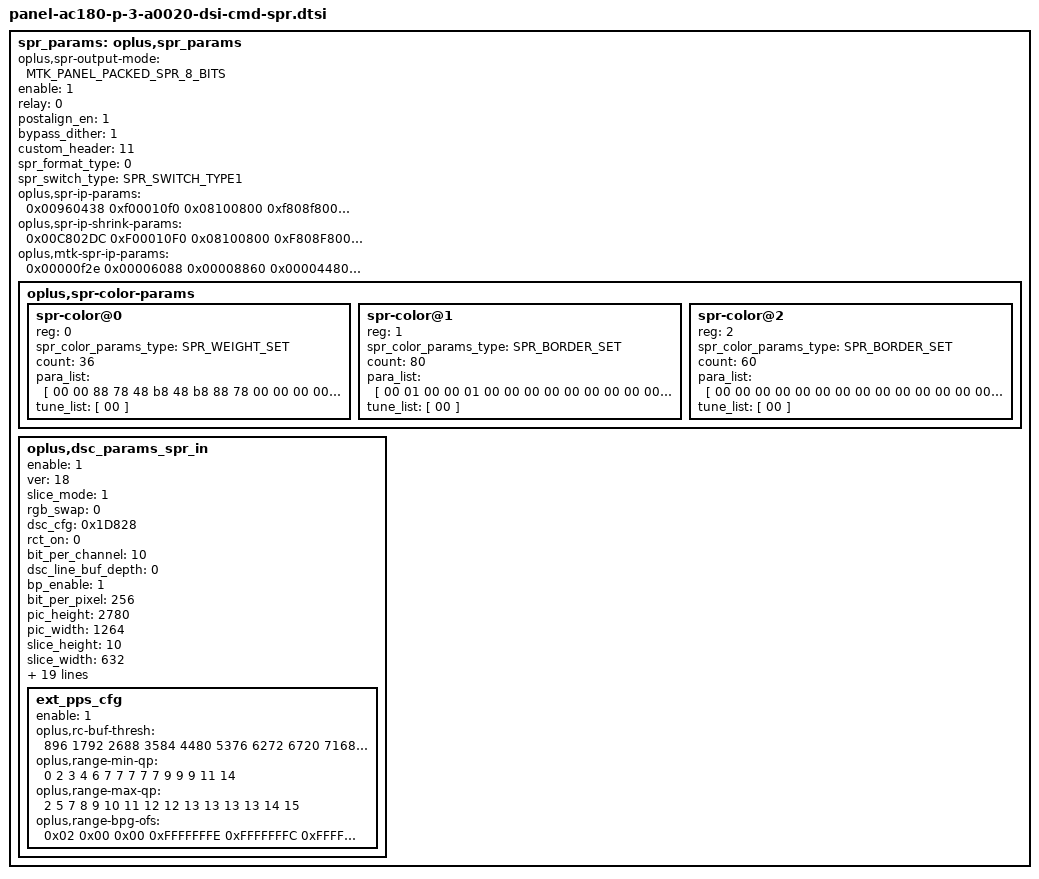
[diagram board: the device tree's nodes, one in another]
	spr_params: oplus,spr_params {
		oplus,spr-output-mode = <MTK_PANEL_PACKED_SPR_8_BITS>;
		enable = <1>;
		relay = <0>;
		postalign_en = <1>;
		bypass_dither = <1>;
		custom_header = <11>;
		spr_format_type = <0>;
		spr_switch_type = <SPR_SWITCH_TYPE1>;
		oplus,spr-ip-params = <
			0x00960438
			0xf00010f0
			0x08100800
			0xf808f800
			0x08000808
			0x00080010
			0x08000000
			0x10120000
			0x00121000
			0x10001012
			0x01f20012
			0x22010001
			0x02000220
			0x20040003
			0x00040003
			0x20040004
			0x20040003
			0x00040003
			0x00040004
			0x80808080
			0x80808040
			0x80408080
			0x00000000
			0x00000000
			0x00000000
			0x00000000
			0x00800000
			0x01080001
			0x08080800
			0x00808080
			0x80808080
			0x08008080
			0x80808080
			0x10533080
			0x50013551
			0x53355335
			0x35011335
			0x55531003
			0x53355335
			0x00000335
			0x00000000
			0x00000000
			0x00000000
			0x00000000
			0x00000000
			0x00000000
			0x00000000
			0x00000000
			0x00000000
			0x00000000
			0x00000000
			0x00000000
			0x00000000
			0x00000000
			0x00000000
			0x00000000
			0x00000000
			0x00000000
			0x00000000
			0x00000000
			0x00000000
			0x00000000
			0x00000000
			0x00000000
			0x00000000
			0x00000000
			0x00000000
			0x00000000
			0x00000000
			0x00000000
			0x00000000
			0x00000000
			0x0000007f
			0x00000000
			0x00000000
			0x00000000
			0x00000000
			0x00000000
			0x00000000
			0x00000000
			0x00000000
			0x00000000
			0x00000000
			0x00000000
			0x00000000
			0x00000000
			0x00000000
			0x00000000
			0x00000000
			0x00000000
			0x00000000
			0x00000000
			0x00000000
			0x00000000
			0x00000000
			0x00000000
			0x00000000
			0x00000000
			0x00000000
			0x00000000
			0x00000000
			0x00000000
			0x00000000
			0x00000000
			0x00000000
			0x00000000
			0x00000000
			0x00000000
			0x00000000
			0x00000000
			0x00000000
			0x00000000
			0x00000000
			0x00000000
			0x00000000
			0x00000000
			0x00000000
			0x00000000
			0x00000000
			0x00000000
			0x00000000
			0x00000000
			0x00000000
			0x00000000
			0x00000000
			0x00000000
			0x00000000
			0x00000000
			0x00000000
			0x00000000
			0x00000000
			0x00000000
			0x00000000
			0x00000000
			0x00000000
			0x00000000
			0x00000000
			0x00000000
			0x00000000
			0x00000000
			0x00000000
			0x00000000
			0x00000000
			0x00000000
			0x00000000
			0x00000000
			0x00000000
			0x00000000
			0x00000000
			0x00000000
			0x00000000
			0x00000000
			0x00000000
			0x00000000
			0x00000000
			0x00000000
			0x00000000
			0x00000000
			0x00000000
			0x00000000
			0x00000000
			0x00000000
			0x00000000
			0x00000000
			0x00000000
			0x00000000
			0x00000000
			0x00000000
			0x00000000
			0x00000000
			0x00000000
			0x00000000
			0x00000000
			0x00000000
			0x00000000
			0x00000000
			0x00000000
			0x00000000
			0x00000000
			0x00000000
			0x00000000
			0x00000000
			0x00000000
			0x00000000
			0x00000000
			0x00000000
			0x00000000
			0x00000000
			0x00000000
			0x00000000
			0x00000000
			0x00000000
			0x00000000
			0x00000000
			0x00000000
			0x00000000
			0x00000000
			0x00000000
			0x00000000
			0x00000000
			0x00000000
			0x00000000
			0x00000000
			0x00000000
			0x00000000
			0x00000000
			0x00000000
			0x00000000
			0x00000000
			0x00000000
			0x00000000
			0x00000000
			0x00000000
			0x00000000
			0x00000000
			0x00004000
			0x00000000
			0x00000000
			0x00000000
			0x00000000
			0x00000000
			0x00000000
			0x00000000
			0x00000000
			0x00000000
			0x00000000
			0x00000000
			0x00000000
			0x00000000
			0x00000000
			0x00000000
			0x00000000
			0x00000000
			0x00000000
			0x00000000
			0x00000000
			0x00000000
			0x00000000
			0x00000000
			0x00000000
			0x00000000
			0x00000000
			0x00000000
			0x00000000
			0x00000000
			0x00000000
			0x00000000
			0x00000000
			0x00000000
			0x00000000
			0x00000000
			0x00000000
			0x00000000
			0x00000000
			0x00000000
			0x00000000
			0x00000000
			0x00000000
			0x00000000
			0x00000000
			0x00000000
			0x00000000
			0x00000000
			0x00000000
			0x00000000
			0x00000000
			0x00000000
			0x00000000
			0x00000000
			0x00000000
			0x00000000
			0x00000000
			0x00000000
			0x00000000
			0x00000000
			0x00000000
			0x00000000
			0x00000000
			0x00000000
			0x00000000
			0x00000000
			0x00000000
			0x00000000
			0x00000000
			0x00000000
			0x00000000
			0x04000000
			0x00000000
			0x00000000
			0x00003000
			0x00000000
			0x00000000
			0x00000000
			0x00000000
			0x00000000
			0x00000000
			0x00000000
			0x00000000
			0x00000000
			0x00000000
			0x00000000
			0x00000000
			0x00000000
			0x00000000
			0x00000000
			0x00000000
			0x00000000
			0x00000000
			0x00000000
			0x00000000
			0x00000000
			0x00000000
			0x00000000
			0x00000000
			0x00000000
			0x00000000
			0x00000000
			0x00000000
			0x00000000
			0x00000000
			0x00000000
			0x00000000
			0x00000000
			0x00000000
			0x00000000
			0x00000000
			0x00000000
			0x00000000
			0x00000000
			0x00000000
			0x00000000
			0x00000000
			0x00000000
			0x00000000
			0x00000000
			0x00000000
			0x00000000
			0x00000000
			0x00000000
			0x00000000
			0x00000000
			0x00000000
			0x00000000
			0x00000000
			0x00000000
			0x00000000
			0x00000000
			0x00000000
			0x00000000
			0x00000000
			0x00000000
			0x00000000
			0x00000000
			0x00000000
			0x00000000
			0x00000000
			0x00000000
			0x00000000
			0x00000000
			0x00000000
			0x00000000
			0x00000000
			0x00000000
			0x00000000
			0x00000000
			0x00000000
			0x00000000
			0x00000000
			0x00000000
			0x00000000
			0x00000000
			0x00000000
			0x00000000
			0x00000000
			0x00000000
			0x00000000
			0x00000000
			0x00000000
			0x00000000
			0x00000000
			0x00000000
			0x00000000
			0x00000000
			0x00000000
			0x00000000
			0x00000000
			0x00000000
			0x00000000
			0x00000000
			0x00000000
			0x00000000
			0x00000000
			0x00000000
			0x00000000
			0x00000000
			0x00000000
			0x00000000
			0x00000000
			0x00000000
			0x00000000
			0x00000000
			0x00000000
			0x00000000
			0x00000000
			0x00000000
			0x00000000
			0x00000000
			0x00000000
			0x00000000
			0x00000000
			0x00000000
			0x00000000
			0x00000000
			0x00000000
			0x00000000
			0x00000000
			0x00000000
			0x00000000
			0x00000000
			0x00000000
			0x00000000
			0x00000000
			0x00000000
			0x00000000
			0x00000000
			0x00000000
			0x00000000
			0x00000000
			0x00000000
			0x00000000
			0x00000000
			0x00000000
			0x00000000
			0x00000000
			0x00000000
			0x00000000
			0x00000000
			0x00000000
			0x00000000
			0x00000000
			0x00000000
			0x00000000
			0x00000000
			0x00000000
			0x00000000
			0x00000000
			0x00000000
			0x00000000
			0x00000000
			0x00000000
			0x00000000
			0x00000000
			0x00000000
			0x00000000
			0x00000000
			0x00000000
			0x00000000
			0x00000000
			0x00000000
			0x00000000
			0x00000000
			0x00000000
			0x00000000
			0x00000000
			0x00000000
			0x00000000
			0x00000000
			0x00000000
			0x00000000
			0x00000000
			0x00000000
			0x00000000
			0x00000000
			0x00000000
			0x00000000
			0x00000000
			0x00000000
			0x00000000
			0x00000000
			0x00000000
			0x00000000
			0x00000000
			0x00000000
			0x00000000
			0x00000000
			0x00000000
			0x00000000
			0x00000000
			0x00000000
			0x00000000
			0x00000000
			0x00000000
			0x00000000
			0x00000000
			0x00000000
			0x00000000
			0x00000000
			0x00000000
			0x00000000
			0x00000000
			0x00000000
			0x00000000
			0x00000000
			0x00000000
			0x00000000
			0x00000000
			0x00000000
			0x00000000
			0x00000000
			0x00000000
			0x00000000
			0x00000000
			0x00000000
			0x00000000
			0x00000000
			0x00000000
			0x00000000
			0x00000000
			0x00000000
			0x00000000
			0x00000000
			0x00000000
			0x00000000
			0x00000000
			0x00000000
			0x00000000
			0x00000000
			0x00000000
			0x00000000
			0x00000000
			0x00000000
			0x00000000
			0x00000000
			0x00000000
			0x00000000
			0x00000000
			0x00000000
			0x00000000
			0x00000000
			0x00000000
			0x00000000
			0x00000000
			0x00000000
			0x00000000
			0x00000000
			0x00000000
			0x00000000
			0x00000000
			0x00000000
			0x00000000
			0x00000000
			0x00000000
			0x00000000
			0x00000000
			0x00000000
			0x00000000
			0x00000000
			0x00000000
			0x00000000
			0x00000000
			0x00000000
			0x00000000
			0x00000000
			0x00000000
			0x00000000
			0x00000000
			0x00000000
			0x00000000
			0x00000000
			0x00000000
			0x00000000
			0x00000000
			0x00000000
			0x00000000
			0x00000000
			0x00000000
			0x00000000
			0x00000000
			0x00000000
			0x00000000
			0x00000000
			0x00000000
			0x00000000
			0x00000000
			0x00000000
			0x00000000
			0x00000000
			0x00000000
			0x00000000
			0x00000000
			0x00000000
			0x00000000
			0x00000000
			0x00000000
			0x00000000
			0x00000000
			0x00000000
			0x00000000
			0x00000000
			0x00000000
			0x00000000
			0x00000000
			0x00000000
			0x00000000
			0x00000000
			0x00000000
			0x00000000
			0x00000000
			0x00000000
			0x00000000
			0x00000000
			0x00000000
			0x00000000
			0x00000000
			0x00000000
			0x00000000
			0x00000000
			0x00000000
			0x00000000
			0x00000000
			0x00000000
			0x00200000
			0x00000000
			0x00000000
			0x00000000
			0x00000000
			0x00000000
			0x00000000
			0x00000000
			0x00000001
			0x00001001
			0x00001001
			0x00001001
			0x00001001
			0x00000000
			0x00000000
			0x00000000
			0x00000000
			0x00000000
			0x00001000
			0x00001001
			0x00001001
			0x00001001
			0x00000001
			0x00000000
			0x00000000
			0x00000000
			0x00000000
			0x00000000
			0x00001001
			0x00001001
			0x00001001
			0x00001001
			0x00000001
			0x00000000
			0x00000000
			0x00000000
			0x00000000
			0x00000000
			0x00000000
			0x00000000
			0x00000000
			0x00000000
			0x00000000
			0x00000000
			0x00000000
			0x00000000
			0x00000000
			0x00000000
			0x00000000
			0x00000000
			0x00000000
			0x00000000
			0x00000000
			0x00000000
			0x00000000
			0x00000000
			0x00000000
			0x00000000
			0x00000000
			0x00000000
			0x00000000
			0x00000000
			0x00000000
			0x00000000
			0x00000000
			0x00000000
			0x00000000
			0x00000000
			0x00000000
			0x00000000
			0x00000000
			0x00000000
			0x00000000
			0x00000000
			0x00000000
			0x00000000
			0x00000000
			0x00000000
			0x00000000
			0x00000000
			0x00000000
			0x00000000
			0x00000000
			0x00000000
			0x00000000
			0x00000000
			0x00000000
			0x00000000
			0x00000000
			0x00000000
			0x00000000
			0x00000000
			0x00000000
			0x00000000
			0x00000000
			0x00000000
			0x00000000
			0x00000000
			0x00000000
			0x00000000
			0x00000000
			0x00000000
			0x00000000
			0x00000000
			0x00000000
			0x00000000
			0x00000000
			0x00000000
			0x00000000
			0x00000000
			0x00000000
			0x00000000
			0x00000000
			0x00000000
			0x00000000
			0x00000000
			0x00000000
			0x00000000
			0x00000000
			0x00000000
			0x00000000
			0x00000000
			0x00000000
			0x00000000
			0x00000000
			0x00000000
			0x00000000
			0x00000000
			0x00000000
			0x00000000
			0x00000000
			0x00000000
			0x00000000
			0x00000000
			0x00000000
			0x00000000
			0x00000000
			0x00000000
			0x00000000
			0x00000000
			0x00000000
			0x00000000
			0x00000000
			0x00000000
			0x00000000
			0x00000000
			0x00000000
			0x00000000
			0x00000000
			0x00000000
			0x00000000
			0x00000000
			0x00000000
			0x00000000
			0x00000000
			0x00000000
			0x00000000
			0x00000000
			0x00000000
			0x00000000
			0x00000000
			0x00000000
			0x00000000
			0x00000000
			0x00000000
			0x00000000
			0x00000000
			0x00000000
			0x00000000
			0x00000000
			0x00000000
			0x00000000
			0x00000000
			0x00000000
			0x00000000
			0x00000000
			0x00000000
			0x00000000
			0x00000000
			0x00000000
			0x00000000
			0x00000000
			0x00000000
			0x00000000
			0x00000000
			0x00000000
			0x00000000
			0x00000000
			0x00000000
			0x00000000
			0x00000000
			0x00000000
			0x00000000
			0x00000000
			0x00000000
			0x00000000
			0x00000000
			0x00000000
			0x00000000
			0x00000000
			0x00000000
			0x00000000
			0x00000000
			0x00000000
			0x00000000
			0x00000000
			0x00000000
			0x00000000
			0x00000000
			0x00000000
			0x00000706
		>;
		oplus,spr-ip-shrink-params = <
			0x00C802DC
			0xF00010F0
			0x08100800
			0xF808F800
			0x08000808
			0x00800010
			0x00800000
			0x10120000
			0x00121000
			0x10001012
			0x01F20012
			0x33010001
			0x02000330
			0x20040414
			0xF0040414
			0x241B0003
			0x20040414
			0xC0040414
			0x191AC003
			0x80805080
			0x80808080
			0x80508080
			0x00000000
			0x00000000
			0x00000000
			0x00000000
			0x00000000
			0x01010000
			0x08080800
			0x00808080
			0x80808080
			0x08008080
			0x80808080
			0x10533080
			0x50013551
			0x53355335
			0x35011335
			0x55531003
			0x53355335
			0x00000335
			0x00000003
			0x00000000
			0x00000000
			0x00000000
			0x00000000
			0x00000000
			0x0000007F
			0x00000000
			0x00000000
			0x00000000
			0x00000000
			0x00000000
			0x00000000
			0x00000000
			0x00000000
			0x00000000
			0x00000000
			0x00000000
			0x00000000
			0x00000000
			0x00000000
			0x00000000
			0x00000000
			0x00000000
			0x00000000
			0x00000000
			0x00000000
			0x00000000
			0x00000000
			0x00000000
			0x00000000
			0x00000000
			0x00000000
			0x00000000
			0x00000000
			0x00000000
			0x00000000
			0x00000000
			0x00000000
			0x00000000
			0x00000000
			0x00000000
			0x00000000
			0x00000000
			0x00000000
			0x00000000
			0x00000000
			0x00000000
			0x00000000
			0x00000000
			0x00000000
			0x00000000
			0x00000000
			0x00000000
			0x00000000
			0x00000000
			0x00000000
			0x00000000
			0x00000000
			0x00000000
			0x00000000
			0x00000000
			0x00000000
			0x00000000
			0x00000000
			0x00000000
			0x00000000
			0x00000000
			0x00000000
			0x00000000
			0x00000000
			0x00004000
			0x00000000
			0x00000000
			0x3e000000
			0x00000000
			0x00000000
			0x00000000
			0x00000000
			0x00000000
			0x00000000
			0x00000000
			0x00000000
		>;
		oplus,mtk-spr-ip-params = <
			0x00000f2e
			0x00006088
			0x00008860
			0x00004480
			0x00006262
			0x00006600
			0x00008080
			0x00004e00
			0x00005050
			0x00005600
			0x00008080
			0x00000e10
			0x00000a0c
			0x00000608
			0x00000204
			0x00000000
			0x000002fd
			0x00000009
			0x00000600
			0x0000400c
			0x00000032
			0x000000a1
			0x00000032
			0xfffffffb
			0x00000027
			0x000000a1
			0x0000003e
			0xfffffffa
			0x0000001d
			0x0000009e
			0x0000004b
			0xfffffffa
			0x00000014
			0x0000009a
			0x00000058
			0xfffffffa
			0x0000000d
			0x00000092
			0x00000065
			0xfffffffc
			0x00000006
			0x00000089
			0x00000073
			0xfffffffe
			0x00000001
			0x0000007e
			0x0000007e
			0x00000001
		>;
		oplus,spr-color-params {
			spr-color@0 {
				reg = <0>;
				spr_color_params_type = <SPR_WEIGHT_SET>;
				count = <36>;
				para_list = [
					00 00 88 78 48 b8 48 b8
					88 78 00 00 00 00 00 00
					00 00 48 b8 88 78 00 00
					00 00 88 78 48 b8 00 00
					00 00 00 00
				];
				tune_list = [
					00
				];
			};
			spr-color@1 {
				reg = <1>;
				spr_color_params_type = <SPR_BORDER_SET>;
				count = <80>;
				para_list = [
					00 01 00 00 01 00 00 00
					00 00 00 00 00 00 00 00
					00 00 00 00 00 00 00 00
					00 00 00 00 00 00 00 00
					00 00 00 00 00 00 00 00
					00 00 00 00 00 00 00 00
					00 00 00 00 00 00 00 00
					00 01 00 00 00 00 00 00
					00 04 00 00 00 00 00 00
					40 80 80 80 80 80 60 80
				];
				tune_list = [
					00
				];
			};
			spr-color@2 {
				reg = <2>;
				spr_color_params_type = <SPR_BORDER_SET>;
				count = <60>;
				para_list = [
					00 00 00 00 00 00 00 00
					00 00 00 00 00 00 00 00
					00 00 00 00 00 00 00 00
					00 00 00 00 00 00 00 00
					00 00 00 00 00 00 00 00
					00 00 00 00 A0 11 A0 11
					A0 11 A0 11 98 11 98 11
					98 11 98 11
				];
				tune_list = [
					00
				];
			};
		};
		oplus,dsc_params_spr_in {
			enable               = <1>;
			ver                  = <18>;
			slice_mode           = <1>;
			rgb_swap             = <0>;
			dsc_cfg              = <0x1D828>;
			rct_on               = <0>;
			bit_per_channel      = <10>;
			dsc_line_buf_depth   = <0>;
			bp_enable            = <1>;
			bit_per_pixel        = <256>;
			pic_height           = <2780>;
			pic_width            = <1264>;
			slice_height         = <10>;
			slice_width          = <632>;
			chunk_size           = <632>;
			xmit_delay           = <341>;
			dec_delay            = <464>;
			scale_value          = <10>;
			increment_interval   = <137>;
			decrement_interval   = <53>;
			line_bpg_offset      = <12>;
			nfl_bpg_offset       = <2731>;
			slice_bpg_offset     = <12551>;
			initial_offset       = <2048>;
			final_offset         = <3088>;
			flatness_minqp       = <7>;
			flatness_maxqp       = <16>;
			rc_model_size        = <8192>;
			rc_edge_factor       = <6>;
			rc_quant_incr_limit0 = <15>;
			rc_quant_incr_limit1 = <15>;
			rc_tgt_offset_hi     = <3>;
			rc_tgt_offset_lo     = <3>;
			ext_pps_cfg {
				enable = <1>;
				oplus,rc-buf-thresh = <
					896 1792 2688 3584 4480 5376 6272 6720 7168 7616 7744 7872 8000 8064
				>;
				oplus,range-min-qp = <
					0 2 3 4 6 7 7 7 7 7 9 9 9 11 14
				>;
				oplus,range-max-qp = <
					2 5 7 8 9 10 11 12 12 13 13 13 13 14 15
				>;
				oplus,range-bpg-ofs = <
					0x02 0x00 0x00 0xFFFFFFFE 0xFFFFFFFC 0xFFFFFFFA 0xFFFFFFF8 0xFFFFFFF8
					0xFFFFFFF8 0xFFFFFFF6 0xFFFFFFF6 0xFFFFFFF4 0xFFFFFFF4 0xFFFFFFF4 0xFFFFFFF4
				>;
			};
		};
	};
